AUTOSAR XML (schema 4.0)
standard types defined: float32, float64, sint16, sint32, sint8, uint16, uint32, uint8, void, boolean
package /ImplDataTypes
  impl type BatteryLevelType: implementation-data-type=uint16, type-emitter=RTE
package /MappingSets
  data type mapping set MappingSet
package /PortInterfaces/SenderReceiver
  sender receiver interface SrIf_BattryInfo
    data BatteryLevel: type=BatteryLevelType
package /SoftwareComponents
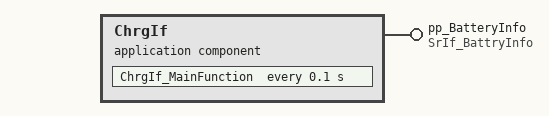
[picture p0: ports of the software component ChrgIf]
  application sw component type ChrgIf
    provide port pp_BatteryInfo: provided-interface=SrIf_BattryInfo
    behavior Ibhv_ChrgIf: data-type-mapping=MappingSet, handle-termination-and-restart=NO-SUPPORT
      timing event TE_ChrgIf_MainFunction_100ms: start-on-event=ChrgIf_MainFunction, period=0.1
      runnable ChrgIf_MainFunction
        data-send-points:
          access DSP_pp_BatteryInfo_BatteryLevel: accessed-variable=pp_BatteryInfo.BatteryLevel
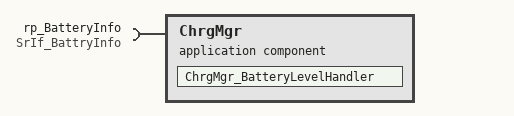
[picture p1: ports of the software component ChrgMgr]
  application sw component type ChrgMgr
    require port rp_BatteryInfo: required-interface=SrIf_BattryInfo
    behavior Ibhv_ChrgMgr: data-type-mapping=MappingSet, handle-termination-and-restart=NO-SUPPORT
      data received event DRE_rp_BatteryInfo_BatteryLevel: start-on-event=ChrgMgr_BatteryLevelHandler, data=rp_BatteryInfo.BatteryLevel
      runnable ChrgMgr_BatteryLevelHandler
        data-receive-point-by-arguments:
          access DRP_rp_BatteryInfo_BatteryLevel: accessed-variable=rp_BatteryInfo.BatteryLevel
  swc implementation Impl_ChrgIf: programming-language=C, sw-version=1.0.0, vendor-id=255, behavior=Ibhv_ChrgIf
    code-descriptors:
      code Code: artifact-descriptors=autosar-engineering-object={short-label=SWC.c, category=SWSRC}
    resource consumption ResourceConsumption
  swc implementation Impl_ChrgMgr: programming-language=C, sw-version=1.0.0, vendor-id=255, behavior=Ibhv_ChrgMgr
    code-descriptors:
      code Code: artifact-descriptors=autosar-engineering-object={short-label=SWC.c, category=SWSRC}
    resource consumption ResourceConsumption
package /Compositions
  composition sw component type OBCAppComposition
    component ChrgIf: type=ChrgIf
    component ChrgMgr: type=ChrgMgr
    connect ChrgIf.pp_BatteryInfo -> ChrgMgr.rp_BatteryInfo
